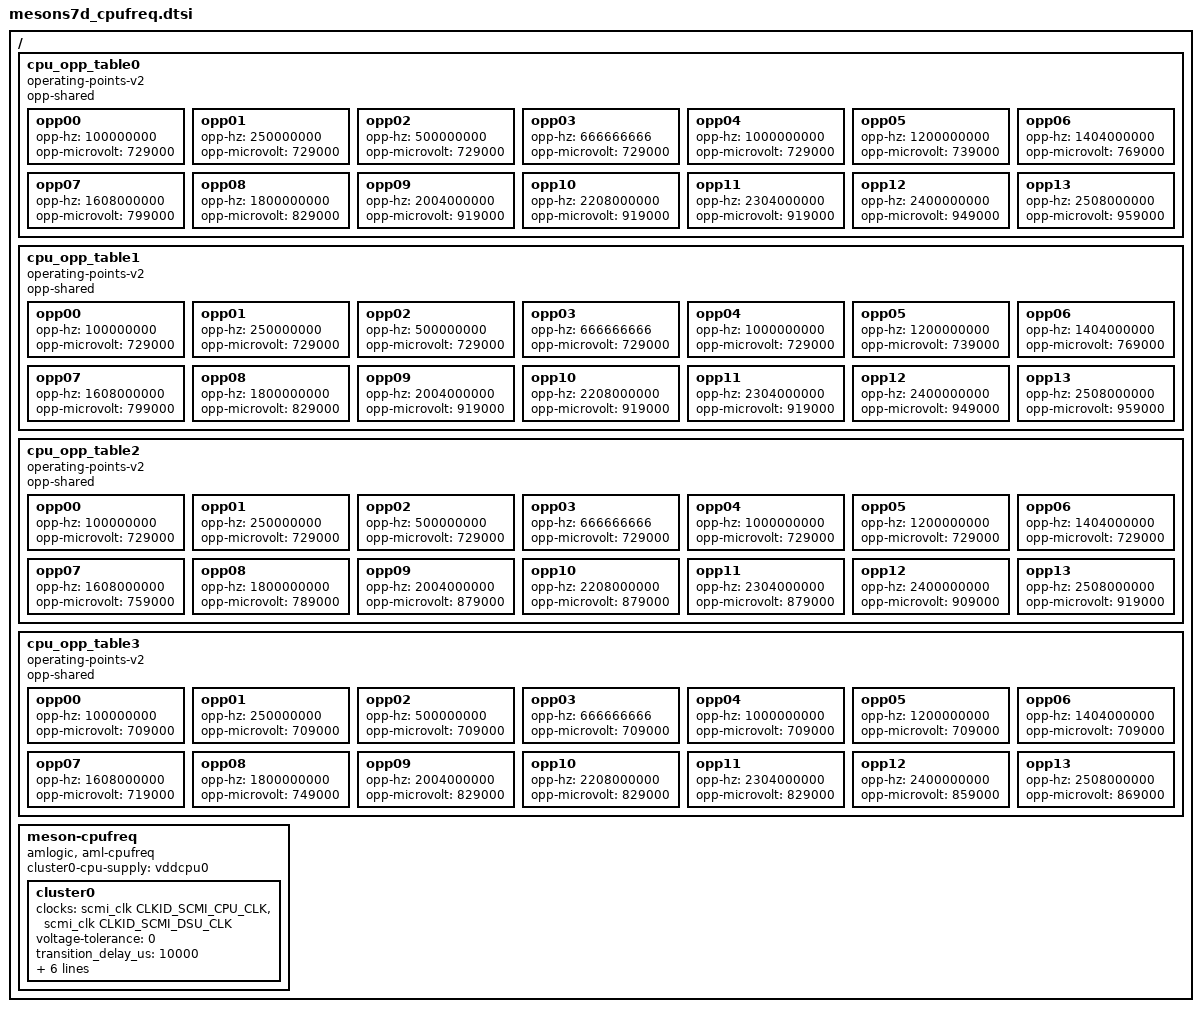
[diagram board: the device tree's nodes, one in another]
// SPDX-License-Identifier: (GPL-2.0+ OR MIT)
/*
 * Copyright (c) 2019 Amlogic, Inc. All rights reserved.
 */
/ {
	cpu_opp_table0: cpu_opp_table0 {
		compatible = "operating-points-v2";
		opp-shared;

		opp00 {
			opp-hz = /bits/ 64 <100000000>;
			opp-microvolt = <729000>;
		};
		opp01 {
			opp-hz = /bits/ 64 <250000000>;
			opp-microvolt = <729000>;
		};
		opp02 {
			opp-hz = /bits/ 64 <500000000>;
			opp-microvolt = <729000>;
		};
		opp03 {
			opp-hz = /bits/ 64 <666666666>;
			opp-microvolt = <729000>;
		};
		opp04 {
			opp-hz = /bits/ 64 <1000000000>;
			opp-microvolt = <729000>;
		};
		opp05 {
			opp-hz = /bits/ 64 <1200000000>;
			opp-microvolt = <739000>;
		};
		opp06 {
			opp-hz = /bits/ 64 <1404000000>;
			opp-microvolt = <769000>;
		};
		opp07 {
			opp-hz = /bits/ 64 <1608000000>;
			opp-microvolt = <799000>;
		};
		opp08 {
			opp-hz = /bits/ 64 <1800000000>;
			opp-microvolt = <829000>;
		};
		opp09 {
			opp-hz = /bits/ 64 <2004000000>;
			opp-microvolt = <919000>;
		};
		opp10 {
			opp-hz = /bits/ 64 <2208000000>;
			opp-microvolt = <919000>;
		};
		opp11 {
			opp-hz = /bits/ 64 <2304000000>;
			opp-microvolt = <919000>;
		};
		opp12 {
			opp-hz = /bits/ 64 <2400000000>;
			opp-microvolt = <949000>;
		};
		opp13 {
			opp-hz = /bits/ 64 <2508000000>;
			opp-microvolt = <959000>;
		};
	};

	cpu_opp_table1: cpu_opp_table1 {
		compatible = "operating-points-v2";
		opp-shared;

		opp00 {
			opp-hz = /bits/ 64 <100000000>;
			opp-microvolt = <729000>;
		};
		opp01 {
			opp-hz = /bits/ 64 <250000000>;
			opp-microvolt = <729000>;
		};
		opp02 {
			opp-hz = /bits/ 64 <500000000>;
			opp-microvolt = <729000>;
		};
		opp03 {
			opp-hz = /bits/ 64 <666666666>;
			opp-microvolt = <729000>;
		};
		opp04 {
			opp-hz = /bits/ 64 <1000000000>;
			opp-microvolt = <729000>;
		};
		opp05 {
			opp-hz = /bits/ 64 <1200000000>;
			opp-microvolt = <739000>;
		};
		opp06 {
			opp-hz = /bits/ 64 <1404000000>;
			opp-microvolt = <769000>;
		};
		opp07 {
			opp-hz = /bits/ 64 <1608000000>;
			opp-microvolt = <799000>;
		};
		opp08 {
			opp-hz = /bits/ 64 <1800000000>;
			opp-microvolt = <829000>;
		};
		opp09 {
			opp-hz = /bits/ 64 <2004000000>;
			opp-microvolt = <919000>;
		};
		opp10 {
			opp-hz = /bits/ 64 <2208000000>;
			opp-microvolt = <919000>;
		};
		opp11 {
			opp-hz = /bits/ 64 <2304000000>;
			opp-microvolt = <919000>;
		};
		opp12 {
			opp-hz = /bits/ 64 <2400000000>;
			opp-microvolt = <949000>;
		};
		opp13 {
			opp-hz = /bits/ 64 <2508000000>;
			opp-microvolt = <959000>;
		};
	};

	cpu_opp_table2: cpu_opp_table2 {
		compatible = "operating-points-v2";
		opp-shared;

		opp00 {
			opp-hz = /bits/ 64 <100000000>;
			opp-microvolt = <729000>;
		};
		opp01 {
			opp-hz = /bits/ 64 <250000000>;
			opp-microvolt = <729000>;
		};
		opp02 {
			opp-hz = /bits/ 64 <500000000>;
			opp-microvolt = <729000>;
		};
		opp03 {
			opp-hz = /bits/ 64 <666666666>;
			opp-microvolt = <729000>;
		};
		opp04 {
			opp-hz = /bits/ 64 <1000000000>;
			opp-microvolt = <729000>;
		};
		opp05 {
			opp-hz = /bits/ 64 <1200000000>;
			opp-microvolt = <729000>;
		};
		opp06 {
			opp-hz = /bits/ 64 <1404000000>;
			opp-microvolt = <729000>;
		};
		opp07 {
			opp-hz = /bits/ 64 <1608000000>;
			opp-microvolt = <759000>;
		};
		opp08 {
			opp-hz = /bits/ 64 <1800000000>;
			opp-microvolt = <789000>;
		};
		opp09 {
			opp-hz = /bits/ 64 <2004000000>;
			opp-microvolt = <879000>;
		};
		opp10 {
			opp-hz = /bits/ 64 <2208000000>;
			opp-microvolt = <879000>;
		};
		opp11 {
			opp-hz = /bits/ 64 <2304000000>;
			opp-microvolt = <879000>;
		};
		opp12 {
			opp-hz = /bits/ 64 <2400000000>;
			opp-microvolt = <909000>;
		};
		opp13 {
			opp-hz = /bits/ 64 <2508000000>;
			opp-microvolt = <919000>;
		};
	};

	cpu_opp_table3: cpu_opp_table3 {
		compatible = "operating-points-v2";
		opp-shared;

		opp00 {
			opp-hz = /bits/ 64 <100000000>;
			opp-microvolt = <709000>;
		};
		opp01 {
			opp-hz = /bits/ 64 <250000000>;
			opp-microvolt = <709000>;
		};
		opp02 {
			opp-hz = /bits/ 64 <500000000>;
			opp-microvolt = <709000>;
		};
		opp03 {
			opp-hz = /bits/ 64 <666666666>;
			opp-microvolt = <709000>;
		};
		opp04 {
			opp-hz = /bits/ 64 <1000000000>;
			opp-microvolt = <709000>;
		};
		opp05 {
			opp-hz = /bits/ 64 <1200000000>;
			opp-microvolt = <709000>;
		};
		opp06 {
			opp-hz = /bits/ 64 <1404000000>;
			opp-microvolt = <709000>;
		};
		opp07 {
			opp-hz = /bits/ 64 <1608000000>;
			opp-microvolt = <719000>;
		};
		opp08 {
			opp-hz = /bits/ 64 <1800000000>;
			opp-microvolt = <749000>;
		};
		opp09 {
			opp-hz = /bits/ 64 <2004000000>;
			opp-microvolt = <829000>;
		};
		opp10 {
			opp-hz = /bits/ 64 <2208000000>;
			opp-microvolt = <829000>;
		};
		opp11 {
			opp-hz = /bits/ 64 <2304000000>;
			opp-microvolt = <829000>;
		};
		opp12 {
			opp-hz = /bits/ 64 <2400000000>;
			opp-microvolt = <859000>;
		};
		opp13 {
			opp-hz = /bits/ 64 <2508000000>;
			opp-microvolt = <869000>;
		};
	};

	meson-cpufreq {
		compatible = "amlogic, aml-cpufreq";
		status = "okay";

		cluster0-cpu-supply = <&vddcpu0>;

		cluster0 {
			clocks = <&scmi_clk CLKID_SCMI_CPU_CLK>, <&scmi_clk CLKID_SCMI_DSU_CLK>;
			clock-names = "cpuclk", "dsuclk";
			voltage-tolerance = <0>;
			transition_delay_us = <10000>;
			//skip_volt_scaling;
			cluster_cores = <0 1 2 3>;
			pdvfs_enabled;
			dsu-opp-table = <1200000 1000000>,
					<1404000 1128000>,
					<1608000 1296000>,
					<1800000 1440000>,
					<2004000 1872000>,
					<2400000 2004000>;
		};
	};
};/* end of / */

